# MSP430G2X32 register map
Vendor: msp430gen; File version: v0.4.0-16-g4f822b9
Registers are 8-bit, read-write, reset 0x0 unless marked. A register's access mark holds for its fields unless they carry their own. Offsets are from the block's base; [hi:lo] are bit positions; {n}, {i} and the like mark numbered series.

## SYSTEM_CLOCK
Base 0x00000052
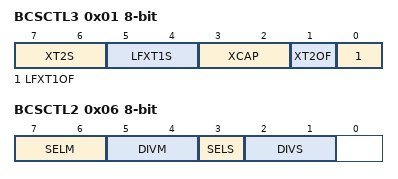
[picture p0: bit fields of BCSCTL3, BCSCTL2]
0x01 BCSCTL3 — Basic Clock System Control 3
  [7:6] XT2S — Mode 0 for XT2
    0=Mode 0 for XT2 : 0.4 - 1 MHz; 1=Mode 1 for XT2 : 1 - 4 MHz; 2=Mode 2 for XT2 : 2 - 16 MHz; 3=Mode 3 for XT2 : Digital input signal
  [5:4] LFXT1S — Mode 0 for LFXT1 (XTS = 0)
    0=Mode 0 for LFXT1 : Normal operation; 1=Mode 1 for LFXT1 : Reserved; 2=Mode 2 for LFXT1 : VLO; 3=Mode 3 for LFXT1 : Digital input signal
  [3:2] XCAP — XIN/XOUT Cap 0
    0=XIN/XOUT Cap : 0 pF; 1=XIN/XOUT Cap : 6 pF; 2=XIN/XOUT Cap : 10 pF; 3=XIN/XOUT Cap : 12.5 pF
  [1] XT2OF — High frequency oscillator 2 fault flag
  [0] LFXT1OF — Low/high Frequency Oscillator Fault Flag
0x04 DCOCTL — DCO Clock Frequency Control
  [7:5] DCO — DCO Select Bit 0
  [7:0] DCOCTL — DCO Clock Frequency Control register
  [4:0] MOD — Modulation Bit 0
0x05 BCSCTL1 — Basic Clock System Control 1
  [7] XT2OFF — Enable XT2CLK
  [6] XTS — LFXTCLK 0:Low Freq. / 1: High Freq.
  [5:4] DIVA — ACLK Divider 0
    0=ACLK Divider 0: /1; 1=ACLK Divider 1: /2; 2=ACLK Divider 2: /4; 3=ACLK Divider 3: /8
  [7:0] BCSCTL1 — Basic Clock System Control 1 register
  [3:0] RSEL — Range Select Bit 0
0x06 BCSCTL2 — Basic Clock System Control 2
  [7:6] SELM — MCLK Source Select 0
    0=MCLK Source Select 0: DCOCLK; 1=MCLK Source Select 1: DCOCLK; 2=MCLK Source Select 2: XT2CLK/LFXTCLK; 3=MCLK Source Select 3: LFXTCLK
  [5:4] DIVM — MCLK Divider 0
    0=MCLK Divider 0: /1; 1=MCLK Divider 1: /2; 2=MCLK Divider 2: /4; 3=MCLK Divider 3: /8
  [3] SELS — SMCLK Source Select 0:DCOCLK / 1:XT2CLK/LFXTCLK
  [2:1] DIVS — SMCLK Divider 0
    0=SMCLK Divider 0: /1; 1=SMCLK Divider 1: /2; 2=SMCLK Divider 2: /4; 3=SMCLK Divider 3: /8

## USI
Base 0x00000078
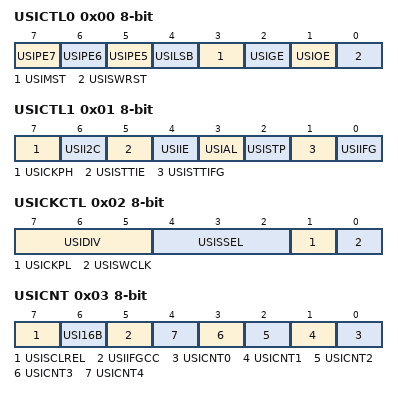
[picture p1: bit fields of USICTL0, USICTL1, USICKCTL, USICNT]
0x00 USICTL0 — USI Control Register 0
  [7] USIPE7 — USI Port Enable Px.7
  [6] USIPE6 — USI Port Enable Px.6
  [5] USIPE5 — USI Port Enable Px.5
  [4] USILSB — USI LSB first 1:LSB / 0:MSB
  [3] USIMST — USI Master Select 0:Slave / 1:Master
  [2] USIGE — USI General Output Enable Latch
  [1] USIOE — USI Output Enable
  [0] USISWRST — USI Software Reset
0x01 USICTL1 — USI Control Register 1
  [7] USICKPH — USI Sync. Mode: Clock Phase
  [6] USII2C — USI I2C Mode
  [5] USISTTIE — USI START Condition interrupt enable
  [4] USIIE — USI Counter Interrupt enable
  [3] USIAL — USI Arbitration Lost
  [2] USISTP — USI STOP Condition received
  [1] USISTTIFG — USI START Condition interrupt Flag
  [0] USIIFG — USI Counter Interrupt Flag
0x02 USICKCTL — USI Clock Control Register
  [7:5] USIDIV — USI Clock Divider 2
    {v}=USI Clock Divider: {v} (v=0..7)
  [4:2] USISSEL — USI Clock Source Select 2
    {v}=USI Clock Source: {v} (v=0..7)
  [1] USICKPL — USI Clock Polarity 0:Inactive=Low / 1:Inactive=High
  [0] USISWCLK — USI Software Clock
0x03 USICNT — USI Bit Counter Register
  [7] USISCLREL — USI SCL Released
  [6] USI16B — USI 16 Bit Shift Register Enable
  [5] USIIFGCC — USI Interrupt Flag Clear Control
  [n] USICNT{n} (n=0..4) — USI Bit Count {n}
0x04 USISRL — USI Low Byte Shift Register
0x05 USISRH — USI High Byte Shift Register

## TLV_CALIBRATION_DATA
Base 0x000010C0
0x00 TLV_CHECKSUM 16-bit
0x1A TLV_ADC10_1_TAG
0x1B TLV_ADC10_1_LEN
0x36 TLV_DCO_30_TAG — TLV TAG_DCO30 TAG
  [7:0] TLV_DCO_30_TAG — TLV TAG_DCO30 TAG register
0x37 TLV_DCO_30_LEN — TLV TAG_DCO30 LEN
  [7:0] TLV_DCO_30_LEN — TLV TAG_DCO30 LEN register

## CALIBRATION_DATA
Base 0x000010F8
0x00 CALDCO_16MHZ — DCOCTL Calibration Data for 16MHz
  [7:0] CALDCO_16MHZ — DCOCTL Calibration Data for 16MHz register
0x01 CALBC1_16MHZ — BCSCTL1 Calibration Data for 16MHz
  [7:0] CALBC1_16MHZ — BCSCTL1 Calibration Data for 16MHz register
0x02 CALDCO_12MHZ — DCOCTL Calibration Data for 12MHz
  [7:0] CALDCO_12MHZ — DCOCTL Calibration Data for 12MHz register
0x03 CALBC1_12MHZ — BCSCTL1 Calibration Data for 12MHz
  [7:0] CALBC1_12MHZ — BCSCTL1 Calibration Data for 12MHz register
0x04 CALDCO_8MHZ — DCOCTL Calibration Data for 8MHz
  [7:0] CALDCO_8MHZ — DCOCTL Calibration Data for 8MHz register
0x05 CALBC1_8MHZ — BCSCTL1 Calibration Data for 8MHz
  [7:0] CALBC1_8MHZ — BCSCTL1 Calibration Data for 8MHz register
0x06 CALDCO_1MHZ — DCOCTL Calibration Data for 1MHz
  [7:0] CALDCO_1MHZ — DCOCTL Calibration Data for 1MHz register
0x07 CALBC1_1MHZ — BCSCTL1 Calibration Data for 1MHz
  [7:0] CALBC1_1MHZ — BCSCTL1 Calibration Data for 1MHz register
